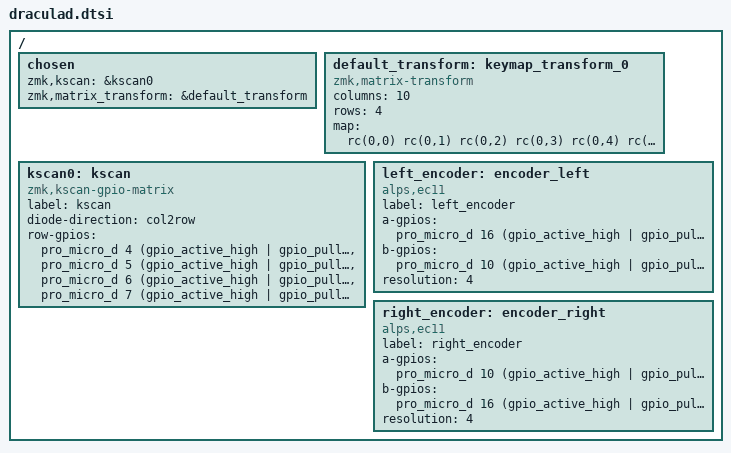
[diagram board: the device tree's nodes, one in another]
/*
 * copyright (c) 2020 the zmk contributors
 *
 * spdx-license-identifier: mit
 */


#include <dt-bindings/zmk/matrix_transform.h>

/ {
    chosen {
        zmk,kscan = &kscan0;
        zmk,matrix_transform = &default_transform;
    };

    default_transform: keymap_transform_0 {
        compatible = "zmk,matrix-transform";
        columns = <10>;
        rows = <4>;
// | sw5  | sw4  | sw3  | sw2  | sw1  |                 | sw1  | sw2  | sw3  | sw4  | sw5  |
// | sw11 | sw10 | sw9  | sw8  | sw7  |                 | sw7  | sw8  | sw9  | sw10 | sw11 |
// | sw17 | sw16 | sw15 | sw14 | sw13 |                 | sw13 | sw14 | sw15 | sw16 | sw17 |
// | sw23 | sw22 | sw21 | sw20 | sw19 | sw25 |   | sw25 | sw19 | sw20 | sw21 | sw22 | sw23 |
//                      | sw28 | sw27 | sw26 |   | sw26 | sw27 | sw28 |
        map = <
rc(0,0) rc(0,1) rc(0,2) rc(0,3) rc(0,4)                         rc(0,5) rc(0,6) rc(0,7) rc(0,8) rc(0,9)
rc(1,0) rc(1,1) rc(1,2) rc(1,3) rc(1,4)                         rc(1,5) rc(1,6) rc(1,7) rc(1,8) rc(1,9)
rc(2,0) rc(2,1) rc(2,2) rc(2,3) rc(2,4) rc(3,1)         rc(3,8) rc(2,5) rc(2,6) rc(2,7) rc(2,8) rc(2,9)
                        rc(3,2) rc(3,3) rc(3,4)         rc(3,5) rc(3,6) rc(3,7)
        >;
    };

    kscan0: kscan {
        compatible = "zmk,kscan-gpio-matrix";
        label = "kscan";

        diode-direction = "col2row";
        row-gpios
            = <&pro_micro_d 4 (gpio_active_high | gpio_pull_down)>
            , <&pro_micro_d 5 (gpio_active_high | gpio_pull_down)>
            , <&pro_micro_d 6 (gpio_active_high | gpio_pull_down)>
            , <&pro_micro_d 7 (gpio_active_high | gpio_pull_down)>
            ;
    };

    left_encoder: encoder_left {
            compatible = "alps,ec11";
            label = "left_encoder";
            /* a-gpios = <&pro_micro_d 16 (gpio_active_high | gpio_pull_up)>; */
            /* b-gpios = <&pro_micro_a 10 (gpio_active_high | gpio_pull_up)>; */
            a-gpios = <&pro_micro_d 16 (gpio_active_high | gpio_pull_up)>;
            b-gpios = <&pro_micro_d 10 (gpio_active_high | gpio_pull_up)>;
            resolution = <4>;
        };

    right_encoder: encoder_right {
            compatible = "alps,ec11";
            label = "right_encoder";
            /* a-gpios = <&pro_micro_a 10 (gpio_active_high | gpio_pull_up)>; */
            /* b-gpios = <&pro_micro_d 16 (gpio_active_high | gpio_pull_up)>; */
            a-gpios = <&pro_micro_d 10 (gpio_active_high | gpio_pull_up)>;
            b-gpios = <&pro_micro_d 16 (gpio_active_high | gpio_pull_up)>;
            resolution = <4>;
    };

    /* sensors { */
            /* compatible = "zmk,keymap-sensors"; */
            /* sensors = <&left_encoder &right_encoder>; */
    /* }; */

};
